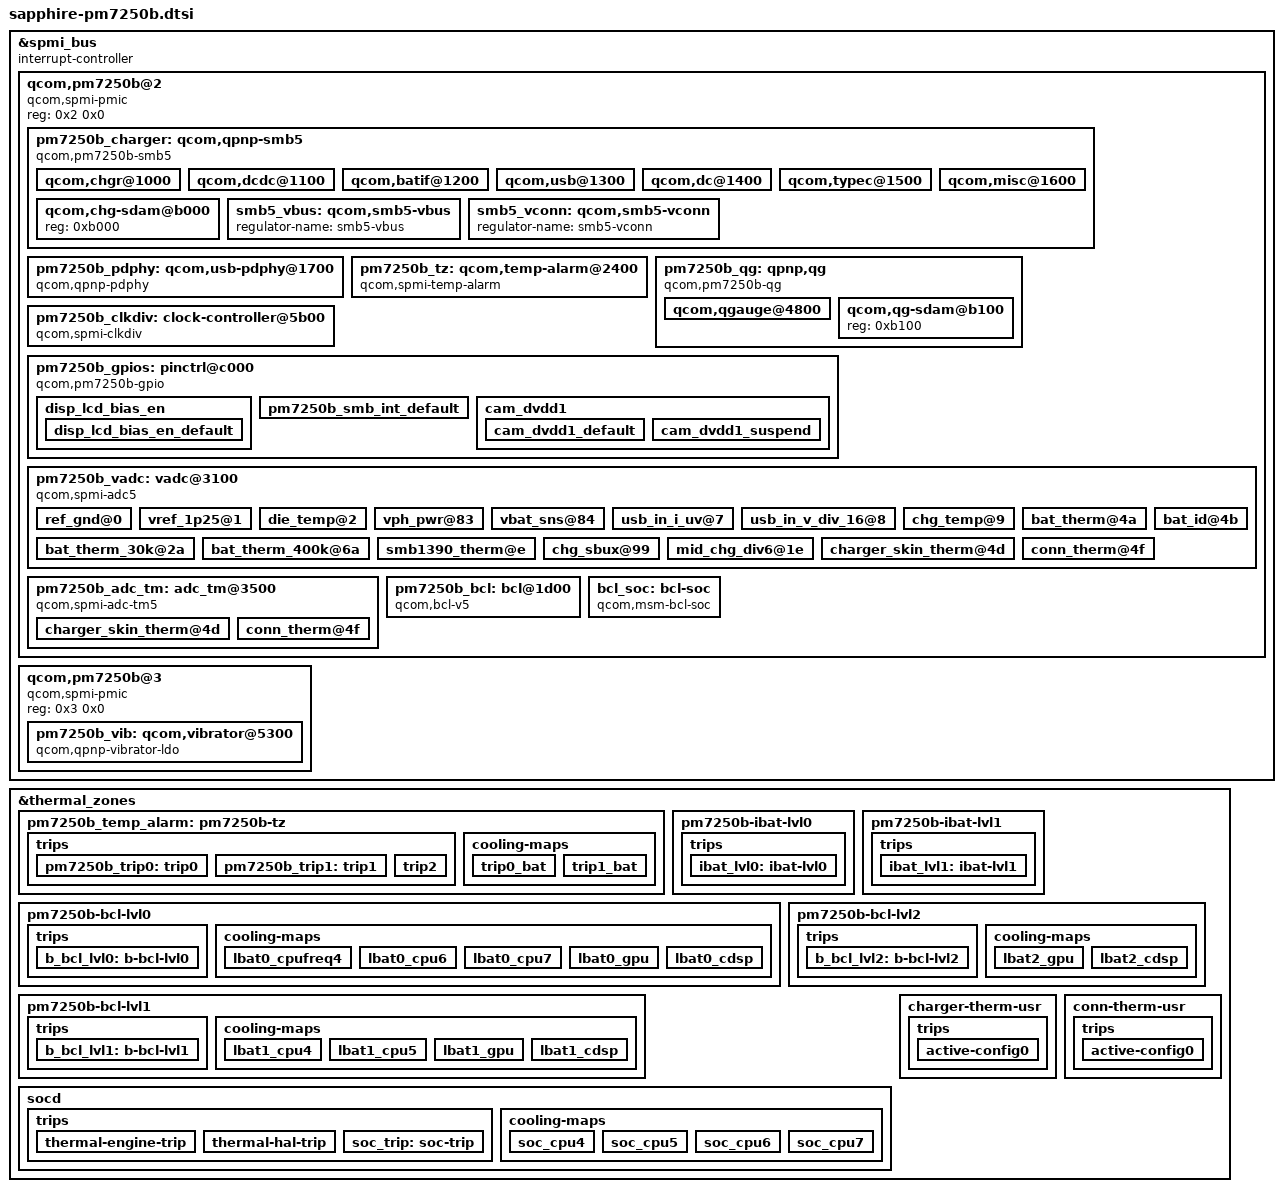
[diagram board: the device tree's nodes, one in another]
// SPDX-License-Identifier: GPL-2.0-only
/*
 * Redmi Note 13 4G (sapphire/sapphiren) - PM7250B PMIC (SMB5 charger, QGauge, PD PHY, ADC, thermal)
 *
 * Reconstructed from the stock dtbo.img (HyperOS OS2.0.215.0.VNHEUXM,
 * entries 45/46) with labels and references restored.  Xiaomi/Longcheer
 * keep this hardware description in their (unpublished) khaje-idp.dtsi /
 * khaje-idp-pm7250b.dtsi; it is split per subsystem here.
 */
#include <dt-bindings/clock/qcom,gcc-khaje.h>
#include <dt-bindings/clock/qcom,rpmcc.h>

&spmi_bus {
	#address-cells = <2>;
	#size-cells = <0>;
	interrupt-controller;
	#interrupt-cells = <4>;

	qcom,pm7250b@2 {
		compatible = "qcom,spmi-pmic";
		reg = <0x2 0x0>;
		#address-cells = <1>;
		#size-cells = <0>;

		pm7250b_charger: qcom,qpnp-smb5 {
			compatible = "qcom,pm7250b-smb5";
			depends-on-supply = <&pm7250b_vadc>;
			#address-cells = <1>;
			#size-cells = <1>;
			#cooling-cells = <2>;
			qcom,thermal-mitigation = <5950000 5400000 5000000 4500000 4000000 3700000 3500000 3000000
			                           2800000 2500000 2000000 1500000 1000000 800000 500000 350000
			                           800000 800000>;
			qcom,hvdcp2-max-icl-ua = <2000000>;
			qcom,hvdcp2-12v-max-icl-ua = <1500000>;
			status = "ok";
			#io-channel-cells = <1>;
			io-channels = <&pm7250b_vadc 8 &pm7250b_vadc 7
			               &pm7250b_vadc 9 &pm7250b_vadc 6
			               &pm7250b_vadc 79 &pm7250b_vadc 153
			               &pm7250b_vadc 131 &pm7250b_vadc 77
			               &pm7250b_qg 75 &pm7250b_qg 162
			               &pm7250b_qg 70 &pm7250b_qg 69
			               &pm7250b_qg 66 &pm7250b_qg 71
			               &pm7250b_qg 93 &pm7250b_qg 78
			               &pm7250b_qg 68 &pm7250b_qg 91
			               &pm7250b_qg 72 &pm7250b_qg 45
			               &pm7250b_qg 83 &pm7250b_qg 73
			               &pm7250b_qg 82 &pm7250b_qg 84
			               &pm7250b_qg 86 &pm7250b_qg 193
			               &sc8541_standalone 152 &sc8541_standalone 157
			               &auth_battery 181 &auth_battery 180
			               &auth_battery 185 &auth_battery 187
			               &bq25960_standalone 152 &bq25960_standalone 157
			               &pm7250b_qg 160 &pm7250b_qg 161
			               &pm7250b_qg 159 &pm7250b_qg 80
			               &bq25960_standalone 196 &pm7250b_charger 197>;
			io-channel-names = "usb_in_voltage", "usb_in_current", "chg_temp", "die_temp", "conn_temp", "sbux_res", "vph_voltage", "skin_temp", "resistance_id", "fastcharge_mode", "voltage_now", "temp", "capacity", "voltage_ocv", "voltage_avg", "debug_battery", "real_capacity", "cc_soc", "current_now", "voltage_max", "charge_full", "charge_counter", "cycle_count", "charge_full_design", "time_to_full_now", "ffc_chg_termination_current", "sc_bus_current", "sc_manufacturer", "auth_batt_id", "auth_authen_result", "auth_manufacturer", "auth_chip_ok", "bq_bus_current", "bq_manufacturer", "soc_decimal", "soc_decimal_rate", "shutdown_delay", "batt_full_current", "bq_set_acdrv", "recharg_mode";
			qcom,battery-data = <&mtp_batterydata>;
			qcom,sec-charger-config = <0>;
			qcom,auto-recharge-soc = <95>;
			qcom,auto-recharge-vbat-mv = <100>;
			qcom,step-charging-enable;
			qcom,sw-jeita-enable;
			mi,use_third_cp;
			mi,support-ffc;
			qcom,distinguish-qc-class-ab;
			qcom,charger-temp-max = <800>;
			qcom,smb-temp-max = <800>;
			qcom,suspend-input-on-debug-batt;
			qcom,fcc-stepping-enable;
			qcom,fcc-step-delay-ms = <100>;
			qcom,fcc-step-size-ua = <100000>;
			qcom,smb-internal-pull-kohm = <0>;
			qcom,en-skin-therm-mitigation;
			qcom,hvdcp3-standalone-config;
			qcom,chg-term-current-ma = <0xffffff06>;
			qcom,fcc-max-ua = <6000000>;
			qcom,fv-max-uv = <4500000>;
			qcom,disable-suspend-on-collapse;
			dpdm-supply = <&usb2_phy0>;

			qcom,chgr@1000 {
				reg = <0x1000>;
				interrupts = <2 16 0 1 2 16 1 1
				              2 16 2 1 2 16 3 1
				              2 16 4 1 2 16 5 1
				              2 16 6 1 2 16 7 1>;
				interrupt-names = "chgr-error", "chg-state-change", "step-chg-state-change", "step-chg-soc-update-fail", "step-chg-soc-update-req", "fg-fvcal-qualified", "vph-alarm", "vph-drop-prechg";
			};

			qcom,dcdc@1100 {
				reg = <0x1100>;
				interrupts = <2 17 0 1 2 17 1 1
				              2 17 2 1 2 17 3 3
				              2 17 4 3 2 17 5 3
				              2 17 6 1 2 17 7 3>;
				interrupt-names = "otg-fail", "otg-oc-disable-sw", "otg-oc-hiccup", "bsm-active", "high-duty-cycle", "input-current-limiting", "concurrent-mode-disable", "switcher-power-ok";
			};

			qcom,batif@1200 {
				reg = <0x1200>;
				interrupts = <2 18 0 1 2 18 2 3
				              2 18 3 3 2 18 4 3
				              2 18 5 3 2 18 6 3
				              2 18 7 3>;
				interrupt-names = "bat-temp", "bat-ov", "bat-low", "bat-therm-or-id-missing", "bat-terminal-missing", "buck-oc", "vph-ov";
			};

			qcom,usb@1300 {
				reg = <0x1300>;
				interrupts = <2 19 0 3 2 19 1 3
				              2 19 2 3 2 19 3 3
				              2 19 4 3 2 19 5 3
				              2 19 6 1 2 19 7 1>;
				interrupt-names = "usbin-collapse", "usbin-vashdn", "usbin-uv", "usbin-ov", "usbin-plugin", "usbin-revi-change", "usbin-src-change", "usbin-icl-change";
			};

			qcom,dc@1400 {
				reg = <0x1400>;
				interrupts = <2 20 1 3 2 20 2 3
				              2 20 3 3 2 20 4 3
				              2 20 5 3 2 20 6 1
				              2 20 7 1>;
				interrupt-names = "dcin-vashdn", "dcin-uv", "dcin-ov", "dcin-plugin", "dcin-revi", "dcin-pon", "dcin-en";
			};

			qcom,typec@1500 {
				reg = <0x1500>;
				interrupts = <2 21 0 1 2 21 1 1
				              2 21 2 1 2 21 3 1
				              2 21 4 1 2 21 5 1
				              2 21 6 1 2 21 7 1>;
				interrupt-names = "typec-or-rid-detect-change", "typec-vpd-detect", "typec-cc-state-change", "typec-vconn-oc", "typec-vbus-change", "typec-attach-detach", "typec-legacy-cable-detect", "typec-try-snk-src-detect";
			};

			qcom,misc@1600 {
				reg = <0x1600>;
				interrupts = <2 22 0 1 2 22 1 1
				              2 22 2 1 2 22 3 1
				              2 22 4 3 2 22 5 1
				              2 22 6 1 2 22 7 1>;
				interrupt-names = "wdog-snarl", "wdog-bark", "aicl-fail", "aicl-done", "smb-en", "imp-trigger", "temp-change", "temp-change-smb";
			};

			qcom,chg-sdam@b000 {
				reg = <0xb000>;
			};

			smb5_vbus: qcom,smb5-vbus {
				regulator-name = "smb5-vbus";
			};

			smb5_vconn: qcom,smb5-vconn {
				regulator-name = "smb5-vconn";
			};
		};

		pm7250b_pdphy: qcom,usb-pdphy@1700 {
			compatible = "qcom,qpnp-pdphy";
			reg = <0x1700>;
			interrupts = <2 23 0 1 2 23 1 1
			              2 23 2 1 2 23 3 1
			              2 23 4 1 2 23 5 1
			              2 23 6 1 2 23 7 1>;
			interrupt-names = "sig-tx", "sig-rx", "msg-tx", "msg-rx", "msg-tx-failed", "msg-tx-discarded", "msg-rx-discarded", "fr-swap";
			#io-channel-cells = <1>;
			qcom,default-sink-caps = <5000 3000 9000 3000 12000 2250>;
			vdd-pdphy-supply = <&L15A>;
			vbus-supply = <&smb5_vbus>;
			vconn-supply = <&smb5_vconn>;
			mi,pd_curr_limit = <1>;
			mi,pd_max_curr_limit = <4000000>;
			mi,limit_pd_unverified_pps_vbus = <1>;
			mi,pd_unverified_pps_max_vbus_limit = <9500000>;
			io-channels = <&pm7250b_charger 4 &pm7250b_charger 3
			               &pm7250b_charger 13 &pm7250b_charger 2
			               &pm7250b_charger 31 &pm7250b_charger 29
			               &pm7250b_charger 30 &pm7250b_charger 0
			               &pm7250b_charger 32 &pm7250b_charger 12
			               &pm7250b_charger 11 &pm7250b_charger 10
			               &pm7250b_charger 1 &pm7250b_charger 7>;
			io-channel-names = "pd_active", "typec_cc_orientation", "connector_type", "typec_power_role", "pd_usb_suspend_supported", "typec_src_rp", "pd_in_hard_reset", "pr_current_max", "pr_swap", "pd_voltage_min", "pd_voltage_max", "real_type", "typec_mode", "pe_start";
		};

		pm7250b_tz: qcom,temp-alarm@2400 {
			compatible = "qcom,spmi-temp-alarm";
			reg = <0x2400>;
			interrupts = <2 36 0 3>;
			io-channels = <&pm7250b_vadc 6>;
			io-channel-names = "thermal";
			#thermal-sensor-cells = <0>;
			qcom,temperature-threshold-set = <1>;
		};

		pm7250b_qg: qpnp,qg {
			compatible = "qcom,pm7250b-qg";
			depends-on-supply = <&pm6125_rtc>;
			#address-cells = <1>;
			#size-cells = <1>;
			qcom,vbatt-cutoff-mv = <3400>;
			qcom,vbatt-low-mv = <3500>;
			qcom,vbatt-low-cold-mv = <3800>;
			qcom,vbatt-empty-mv = <3000>;
			qcom,vbatt-empty-cold-mv = <3000>;
			qcom,s3-entry-fifo-length = <2>;
			qcom,soc_decimal_rate = <0 32 10 30 20 28 30 28
			                         40 28 50 28 60 28 70 28
			                         80 28 90 26 95 10 99 5>;
			status = "ok";
			#io-channel-cells = <1>;
			io-channels = <&pm7250b_vadc 42 &pm7250b_vadc 75
			               &pm7250b_charger 55 &pm7250b_charger 63
			               &pm7250b_charger 64 &pm7250b_charger 57
			               &sc8541_standalone 118 &sc8541_standalone 148
			               &bq25960_standalone 118 &bq25960_standalone 148
			               &pm7250b_charger 10>;
			io-channel-names = "batt-therm", "batt-id", "input_current_limited", "recharge_soc", "force_recharge", "charge_done", "charging_enabled", "sc_battery_voltage", "bq_charging_enabled", "bq_battery_voltage", "real_type";
			qcom,battery-data = <&mtp_batterydata>;
			qcom,qg-iterm-ma = <300>;
			qcom,hold-soc-while-full;
			qcom,linearize-soc;
			qcom,cl-feedback-on;
			qcom,tcss-enable;
			qcom,fvss-enable;
			qcom,fvss-vbatt-mv = <3600>;
			qcom,bass-enable;
			qcom,s3-entry-ibat-ua = <25000>;
			qcom,s3-exit-ibat-ua = <45000>;
			qcom,qg-ext-sns;
			qcom,shutdown-delay-enable;

			qcom,qgauge@4800 {
				status = "okay";
				reg = <0x4800>;
				interrupts = <2 72 0 3 2 72 1 3
				              2 72 2 1 2 72 3 1
				              2 72 4 1>;
				interrupt-names = "qg-batt-missing", "qg-vbat-low", "qg-vbat-empty", "qg-fifo-done", "qg-good-ocv";
			};

			qcom,qg-sdam@b100 {
				status = "okay";
				reg = <0xb100>;
			};
		};

		pm7250b_clkdiv: clock-controller@5b00 {
			compatible = "qcom,spmi-clkdiv";
			reg = <0x5b00>;
			#clock-cells = <1>;
			qcom,num-clkdivs = <1>;
			clock-output-names = "pm7250b_div_clk1";
			clocks = <&rpmcc RPM_PXO_CLK>;
			clock-names = "xo";
			assigned-clocks = <&pm7250b_clkdiv 1>;
			assigned-clock-rates = <19200000>;
		};

		pm7250b_gpios: pinctrl@c000 {
			compatible = "qcom,pm7250b-gpio";
			reg = <0xc000>;
			gpio-controller;
			#gpio-cells = <2>;
			interrupt-controller;
			#interrupt-cells = <2>;

			disp_lcd_bias_en {
				disp_lcd_bias_en_default: disp_lcd_bias_en_default {
					pins = "gpio5";
					function = "func1";
					input-disable;
					output-enable;
					bias-disable;
					power-source = <0>;
					qcom,drive-strength = <2>;
				};
			};

			pm7250b_smb_int_default: pm7250b_smb_int_default {
				pins = "gpio6";
				function = "gpio";
				input-enable;
				bias-pull-up;
				qcom,pull-up-strength = <0>;
				power-source = <0>;
			};

			cam_dvdd1 {
				cam_dvdd1_default: cam_dvdd1_default {
					pins = "gpio3";
					function = "normal";
					input-disable;
					output-high;
					bias-disable;
					power-source = <0>;
					qcom,drive-strength = <3>;
				};

				cam_dvdd1_suspend: cam_dvdd1_suspend {
					pins = "gpio3";
					function = "normal";
					input-disable;
					output-low;
					bias-disable;
					power-source = <0>;
					qcom,drive-strength = <3>;
				};
			};
		};

		pm7250b_vadc: vadc@3100 {
			compatible = "qcom,spmi-adc5";
			reg = <0x3100>;
			reg-names = "adc5-usr-base";
			#address-cells = <1>;
			#size-cells = <0>;
			interrupts = <2 49 0 1>;
			interrupt-names = "eoc-int-en-set";
			qcom,adc-vdd-reference = <1875>;
			#io-channel-cells = <1>;
			io-channel-ranges;

			ref_gnd@0 {
				reg = <0x0>;
				label = "ref_gnd";
				qcom,pre-scaling = <1 1>;
			};

			vref_1p25@1 {
				reg = <0x1>;
				label = "vref_1p25";
				qcom,pre-scaling = <1 1>;
			};

			die_temp@2 {
				reg = <0x6>;
				label = "die_temp";
				qcom,pre-scaling = <1 1>;
			};

			vph_pwr@83 {
				reg = <0x83>;
				label = "vph_pwr";
				qcom,pre-scaling = <1 3>;
			};

			vbat_sns@84 {
				reg = <0x84>;
				label = "vbat_sns";
				qcom,pre-scaling = <1 3>;
			};

			usb_in_i_uv@7 {
				reg = <0x7>;
				label = "usb_in_i_uv";
				qcom,pre-scaling = <1 1>;
			};

			usb_in_v_div_16@8 {
				reg = <0x8>;
				label = "usb_in_v_div_16";
				qcom,pre-scaling = <1 16>;
			};

			chg_temp@9 {
				reg = <0x9>;
				label = "chg_temp";
				qcom,pre-scaling = <1 1>;
			};

			bat_therm@4a {
				reg = <0x4a>;
				label = "bat_therm";
				qcom,ratiometric;
				qcom,hw-settle-time = <200>;
				qcom,pre-scaling = <1 1>;
			};

			bat_therm_30k@2a {
				reg = <0x2a>;
				label = "bat_therm_30k";
				qcom,ratiometric;
				qcom,hw-settle-time = <200>;
				qcom,pre-scaling = <1 1>;
			};

			bat_therm_400k@6a {
				reg = <0x6a>;
				label = "bat_therm_400k";
				qcom,ratiometric;
				qcom,hw-settle-time = <200>;
				qcom,pre-scaling = <1 1>;
			};

			bat_id@4b {
				reg = <0x4b>;
				label = "bat_id";
				qcom,ratiometric;
				qcom,hw-settle-time = <200>;
				qcom,pre-scaling = <1 1>;
			};

			smb1390_therm@e {
				reg = <0xe>;
				label = "smb1390_therm";
				qcom,hw-settle-time = <200>;
				qcom,pre-scaling = <1 1>;
			};

			chg_sbux@99 {
				reg = <0x99>;
				label = "chg_sbux";
				qcom,pre-scaling = <1 3>;
			};

			mid_chg_div6@1e {
				reg = <0x1e>;
				label = "chg_mid";
				qcom,pre-scaling = <1 6>;
			};

			charger_skin_therm@4d {
				reg = <0x4d>;
				label = "charger_skin_therm";
				qcom,ratiometric;
				qcom,hw-settle-time = <200>;
				qcom,pre-scaling = <1 1>;
			};

			conn_therm@4f {
				reg = <0x4f>;
				label = "conn_therm";
				qcom,ratiometric;
				qcom,hw-settle-time = <200>;
				qcom,pre-scaling = <1 1>;
			};
		};

		pm7250b_adc_tm: adc_tm@3500 {
			compatible = "qcom,spmi-adc-tm5";
			reg = <0x3500>;
			interrupts = <2 53 0 1>;
			interrupt-names = "pm-adc-tm5";
			#address-cells = <1>;
			#size-cells = <0>;
			#thermal-sensor-cells = <1>;
			status = "ok";

			charger_skin_therm@4d {
				reg = <0x0>;
				io-channels = <&pm7250b_vadc 77>;
				qcom,ratiometric;
				qcom,hw-settle-time-us = <200>;
			};

			conn_therm@4f {
				reg = <0x1>;
				io-channels = <&pm7250b_vadc 79>;
				qcom,ratiometric;
				qcom,hw-settle-time-us = <200>;
			};
		};

		pm7250b_bcl: bcl@1d00 {
			compatible = "qcom,bcl-v5";
			reg = <0x1d00>;
			interrupts = <2 29 0 0 2 29
			              1 0 2 29 2 0>;
			interrupt-names = "bcl-lvl0", "bcl-lvl1", "bcl-lvl2";
			#thermal-sensor-cells = <1>;
		};

		bcl_soc: bcl-soc {
			compatible = "qcom,msm-bcl-soc";
			#thermal-sensor-cells = <0>;
		};
	};

	qcom,pm7250b@3 {
		compatible = "qcom,spmi-pmic";
		reg = <0x3 0x0>;
		#address-cells = <1>;
		#size-cells = <0>;

		pm7250b_vib: qcom,vibrator@5300 {
			compatible = "qcom,qpnp-vibrator-ldo";
			reg = <0x5300>;
			qcom,vib-ldo-volt-uv = <3000000>;
			qcom,disable-overdrive;
		};
	};
};

&thermal_zones {
	pm7250b_temp_alarm: pm7250b-tz {
		polling-delay-passive = <100>;
		polling-delay = <0>;
		thermal-sensors = <&pm7250b_tz>;

		trips {
			pm7250b_trip0: trip0 {
				temperature = <95000>;
				hysteresis = <0>;
				type = "passive";
			};

			pm7250b_trip1: trip1 {
				temperature = <115000>;
				hysteresis = <0>;
				type = "passive";
			};

			trip2 {
				temperature = <145000>;
				hysteresis = <0>;
				type = "passive";
			};
		};
	};

	pm7250b-ibat-lvl0 {
		polling-delay-passive = <0>;
		polling-delay = <0>;
		thermal-sensors = <&pm7250b_bcl 0>;

		trips {
			ibat_lvl0: ibat-lvl0 {
				temperature = <5500>;
				hysteresis = <200>;
				type = "passive";
			};
		};
	};

	pm7250b-ibat-lvl1 {
		polling-delay-passive = <0>;
		polling-delay = <0>;
		thermal-sensors = <&pm7250b_bcl 1>;

		trips {
			ibat_lvl1: ibat-lvl1 {
				temperature = <6000>;
				hysteresis = <200>;
				type = "passive";
			};
		};
	};

	pm7250b-bcl-lvl0 {
		polling-delay-passive = <100>;
		polling-delay = <0>;
		thermal-sensors = <&pm7250b_bcl 5>;

		trips {
			b_bcl_lvl0: b-bcl-lvl0 {
				temperature = <1>;
				hysteresis = <1>;
				type = "passive";
			};
		};
	};

	pm7250b-bcl-lvl1 {
		polling-delay-passive = <100>;
		polling-delay = <0>;
		thermal-sensors = <&pm7250b_bcl 6>;

		trips {
			b_bcl_lvl1: b-bcl-lvl1 {
				temperature = <1>;
				hysteresis = <1>;
				type = "passive";
			};
		};
	};

	pm7250b-bcl-lvl2 {
		polling-delay-passive = <100>;
		polling-delay = <0>;
		thermal-sensors = <&pm7250b_bcl 7>;

		trips {
			b_bcl_lvl2: b-bcl-lvl2 {
				temperature = <1>;
				hysteresis = <1>;
				type = "passive";
			};
		};
	};

	socd {
		polling-delay-passive = <100>;
		polling-delay = <0>;

		trips {
			thermal-engine-trip {
				temperature = <100>;
				hysteresis = <0>;
				type = "passive";
			};

			thermal-hal-trip {
				temperature = <100>;
				hysteresis = <0>;
				type = "passive";
			};

			soc_trip: soc-trip {
				temperature = <90>;
				hysteresis = <0>;
				type = "passive";
			};
		};
	};
};

&thermal_zones {
	charger-therm-usr {
		polling-delay-passive = <0>;
		polling-delay = <0>;
		thermal-governor = "user_space";
		thermal-sensors = <&pm7250b_adc_tm 0>;
		wake-capable-sensor;

		trips {
			active-config0 {
				temperature = <125000>;
				hysteresis = <1000>;
				type = "passive";
			};
		};
	};

	conn-therm-usr {
		polling-delay-passive = <0>;
		polling-delay = <0>;
		thermal-governor = "user_space";
		thermal-sensors = <&pm7250b_adc_tm 1>;
		wake-capable-sensor;

		trips {
			active-config0 {
				temperature = <125000>;
				hysteresis = <1000>;
				type = "passive";
			};
		};
	};
};

&thermal_zones {
	pm7250b-tz {
		cooling-maps {
			trip0_bat {
				trip = <&pm7250b_trip0>;
				cooling-device = <&pm7250b_charger 9 9>;
			};

			trip1_bat {
				trip = <&pm7250b_trip1>;
				cooling-device = <&pm7250b_charger 10 10>;
			};
		};
	};

	socd {
		cooling-maps {
			soc_cpu4 {
				trip = <&soc_trip>;
				cooling-device = <&cpu4_pause 1 1>;
			};

			soc_cpu5 {
				trip = <&soc_trip>;
				cooling-device = <&cpu5_pause 1 1>;
			};

			soc_cpu6 {
				trip = <&soc_trip>;
				cooling-device = <&cpu6_pause 1 1>;
			};

			soc_cpu7 {
				trip = <&soc_trip>;
				cooling-device = <&cpu7_pause 1 1>;
			};
		};
	};

	pm7250b-bcl-lvl0 {
		cooling-maps {
			lbat0_cpufreq4 {
				trip = <&b_bcl_lvl0>;
				cooling-device = <&CPU4 2 2>;
			};

			lbat0_cpu6 {
				trip = <&b_bcl_lvl0>;
				cooling-device = <&cpu6_pause 1 1>;
			};

			lbat0_cpu7 {
				trip = <&b_bcl_lvl0>;
				cooling-device = <&cpu7_pause 1 1>;
			};

			lbat0_gpu {
				trip = <&b_bcl_lvl0>;
				cooling-device = <&msm_gpu 2 2>;
			};

			lbat0_cdsp {
				trip = <&b_bcl_lvl0>;
				cooling-device = <&cdsp_sw 2 2>;
			};
		};
	};

	pm7250b-bcl-lvl1 {
		cooling-maps {
			lbat1_cpu4 {
				trip = <&b_bcl_lvl1>;
				cooling-device = <&cpu4_pause 1 1>;
			};

			lbat1_cpu5 {
				trip = <&b_bcl_lvl1>;
				cooling-device = <&cpu5_pause 1 1>;
			};

			lbat1_gpu {
				trip = <&b_bcl_lvl1>;
				cooling-device = <&msm_gpu 4 4>;
			};

			lbat1_cdsp {
				trip = <&b_bcl_lvl1>;
				cooling-device = <&cdsp_sw 4 4>;
			};
		};
	};

	pm7250b-bcl-lvl2 {
		cooling-maps {
			lbat2_gpu {
				trip = <&b_bcl_lvl2>;
				cooling-device = <&msm_gpu 4 0xffffffff>;
			};

			lbat2_cdsp {
				trip = <&b_bcl_lvl2>;
				cooling-device = <&cdsp_sw 4 4>;
			};
		};
	};
};
